# NUC123AE_v1 register map
File version: 1.0
Registers are 32-bit, read-write, reset 0x0 unless marked. A register's access mark holds for its fields unless they carry their own. Offsets are from the block's base; [hi:lo] are bit positions; {n}, {i} and the like mark numbered series; 'fields as' and 'values as' point back to an identical list.

## CLK — CLK Register Map
Base 0x50000200
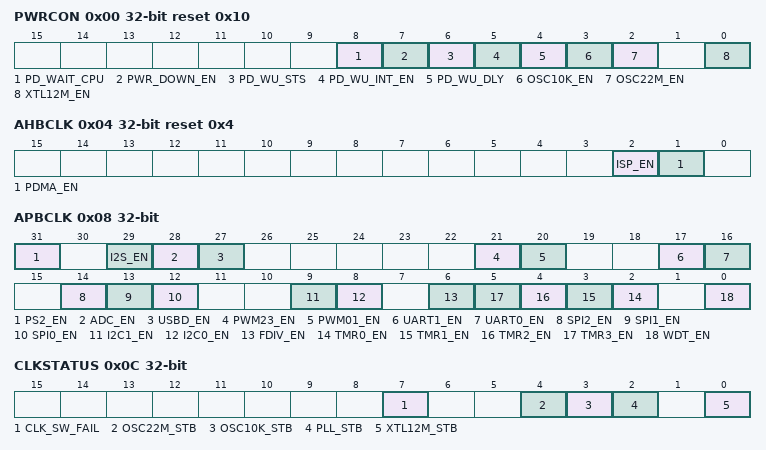
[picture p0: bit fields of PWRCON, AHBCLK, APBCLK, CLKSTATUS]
0x00 PWRCON reset 0x10 (reset mask 0xFFFFFFF0) — System Power-down Control Register
  [8] PD_WAIT_CPU — Power-down Entry Conditions Control (Write-protection Bit)
    0=Chip entering Power-down mode when the PWR_DOWN_EN bit is set to 1; 1=Chip entering Power-down mode when the both PD_WAIT_CPU and PWR_DOWN_EN bits are set to 1 and CPU run WFI instruction
  [7] PWR_DOWN_EN — System Power-down Enable Bit (Write-protection Bit). When this bit is set to 1, the chip Power-down mode is enabled and chip Power-down behavior will depend on the PD_WAIT_CPU bit. (a) If the PD_WAIT_CPU is 0, the chip enters Power-down mode immediately after the PWR_DOWN_EN bit set. (b) If the PD_WAIT_CPU is 1, the chip keeps active till the CPU sleep mode is also active and then the chip enters Power-down mode. When chip wakes up from Power-down mode, this bit is auto cleared. User needs to set this bit again for next Power-down. In Power-down mode, external 4~24 MHz high speed crystal and the internal 22.1184 MHz high speed oscillator will be disabled in this mode, but the external 32.768 kHz low speed crystal and internal 10 kHz low speed oscillator are not controlled by Power-down mode. In Power-down mode, the PLL and system clock are disabled, and ignored the clock source selection. The clocks of peripheral are not controlled by Power-down mode, if the peripheral clock source is from external 32.768 kHz low speed crystal or the internal 10 kHz low speed oscillator.
    0=Chip operating normally or chip in Idle mode because of WFI command; 1=Chip entering the Power-down mode instantly or wait CPU sleep command WFI
  [6] PD_WU_STS — Power-down Mode Wake-up Interrupt Status. Set by "Power-down wake-up event", which indicates that resume from Power-down mode" The flag is set if the GPIO, USB, UART, WDT or BOD wake-up occurred. Write 1 to clear the bit to zero. Note: This bit works only when PD_WU_INT_EN (PWRCON[5]) set to 1.
  [5] PD_WU_INT_EN — Power-down Mode Wake-up Interrupt Enable (Write-protection Bit). The interrupt will occur when both PD_WU_STS and PD_WU_INT_EN are high.
    0=Disabled; 1=Enabled
  [4] PD_WU_DLY — Enable the Wake-up Delay Counter (Write-protection Bit). When the chip wakes up from Power-down mode, the clock control will delay certain clock cycles to wait system clock stable. The delayed clock cycle is 4096 clock cycles when chip work at external 4~24 MHz high speed crystal, and 256 clock cycles when chip work at internal 22.1184 MHz high speed oscillator.
    0=Clock cycles delay Disabled; 1=Clock cycles delay Enabled
  [3] OSC10K_EN — Internal 10 kHz Low Speed Oscillator Enable (Write-protection Bit)
    0=Internal 10 kHz low speed oscillator Disabled; 1=Internal 10 kHz low speed oscillator Enabled
  [2] OSC22M_EN — Internal 22.1184 MHz High Speed Oscillator Enable (Write-protection Bit)
    0=Internal 22.1184 MHz high speed oscillator Disabled; 1=Internal 22.1184 MHz high speed oscillator Enabled
  [0] XTL12M_EN — External 4~24 MHz High Speed Crystal Enable (Write-protection Bit). The bit default value is set by flash controller user configuration register config0 [26:24]. When the default clock source is from external 4~24 MHz high speed crystal, this bit is set to 1 automatically
    0=External 4~24 MHz high speed crystal Disabled; 1=External 4~24 MHz high speed crystal Enabled
0x04 AHBCLK reset 0x4 — AHB Devices Clock Enable Control Register
  [2] ISP_EN — Flash ISP Controller Clock Enable Control
    0=Flash ISP engine clock Disabled; 1=Flash ISP engine clock Enabled
  [1] PDMA_EN — PDMA Controller Clock Enable Control
    0=PDMA engine clock Disabled; 1=PDMA engine clock Enabled
0x08 APBCLK (reset mask 0xFFFFFFF0) — APB Devices Clock Enable Control Register
  [31] PS2_EN — PS/2 Clock Enable
    0=PS/2 clock Disabled; 1=PS/2 clock Enabled
  [29] I2S_EN — I2S Clock Enable
    0=I2S Clock Disabled; 1=I2S Clock Enabled
  [28] ADC_EN — Analog-Digital-Converter (ADC) Clock Enable
    0=ADC clock Disabled; 1=ADC clock Enabled
  [27] USBD_EN — USB 2.0 FS Device Controller Clock Enable
    0=USB clock Disabled; 1=USB clock Enabled
  [21] PWM23_EN — PWM_23 Clock Enable
    0=PWM23 clock Disabled; 1=PWM23 clock Enabled
  [20] PWM01_EN — PWM_01 Clock Enable
    0=PWM01 clock Disabled; 1=PWM01 clock Enabled
  [17] UART1_EN — UART1 Clock Enable
    0=UART1 clock Disabled; 1=UART1 clock Enabled
  [16] UART0_EN — UART0 Clock Enable
    0=UART0 clock Disabled; 1=UART0 clock Enabled
  [14] SPI2_EN — SPI2 Clock Enable
    0=SPI2 clock Disabled; 1=SPI2 clock Enabled
  [13] SPI1_EN — SPI1 Clock Enable
    0=SPI1 clock Disabled; 1=SPI1 clock Enabled
  [12] SPI0_EN — SPI0 Clock Enable
    0=SPI0 clock Disabled; 1=SPI0 clock Enabled
  [9] I2C1_EN — I2C1 Clock Enable
    0=I2C1 clock Disabled; 1=I2C1 clock Enabled
  [8] I2C0_EN — I2C0 Clock Enable
    0=I2C0 clock Disabled; 1=I2C0 clock Enabled
  [6] FDIV_EN — Frequency Divider Output Clock Enable
    0=FDIV clock Disabled; 1=FDIV clock Enabled
  [n+2] TMR{n}_EN (n=0..3) — Timer{n} Clock Enable
    0=Timer{n} clock Disabled; 1=Timer{n} clock Enabled
  [0] WDT_EN — Watchdog Timer Clock Enable (Write-protection Bit). This bit is the protected bit, which means programming it needs to write "59h", "16h", "88h" to address 0x5000_0100 to disable register protection. Refer to the register REGWRPROT at address GCR_BA+0x100.
    0=Watchdog Timer Clock Disabled; 1=Watchdog Timer Clock Enabled
0x0C CLKSTATUS (reset mask 0xFFFFFF00) — Clock Status Monitor Register
  [7] CLK_SW_FAIL — Clock Switching Fail Flag. This bit is an index that if current system clock source is match as user defined at HCLK_S (CLKSEL[2:0]). When user switch system clock, the system clock source will keep old clock until the new clock is stable. During the period that waiting new clock stable, this bit will be an index shows system clock source is not match as user wanted. This bit is read only.
    0=Clock switching success; 1=Clock switching failure
  [4] OSC22M_STB — Internal 22.1184 MHz High Speed Oscillator Clock Source Stable Flag. This is read only bit
    0=Internal 22.1184 MHz high speed oscillator clock is not stable or disabled; 1=Internal 22.1184 MHz high speed oscillator clock is stable
  [3] OSC10K_STB — Internal 10 kHz Low Speed Oscillator Clock Source Stable Flag. This is read only bit.
    0=Internal 10 kHz low speed oscillator clock is not stable or disabled; 1=Internal 10 kHz low speed oscillator clock is stable
  [2] PLL_STB — Internal PLL Clock Source Stable Flag. This is read only bit.
    0=Internal PLL clock is not stable or disabled; 1=Internal PLL clock is stable
  [0] XTL12M_STB — External 4~24 MHz High Speed Crystal Clock Source Stable Flag. This is read only bit.
    0=External 4~24 MHz high speed crystal clock is not stable or disabled; 1=External 4~24 MHz high speed crystal clock is stable
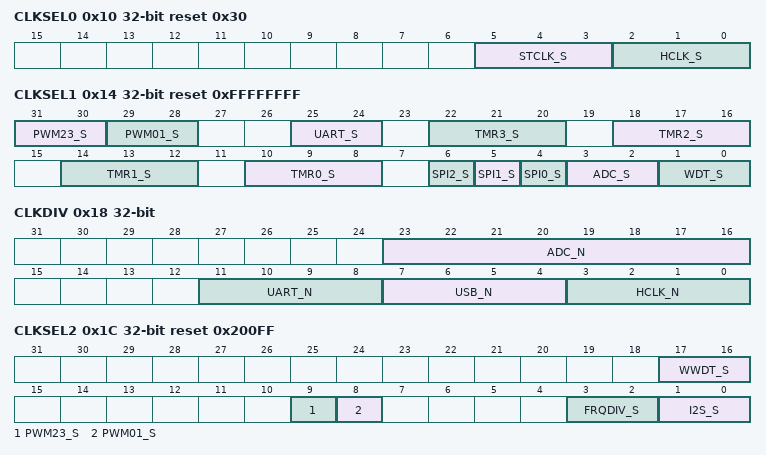
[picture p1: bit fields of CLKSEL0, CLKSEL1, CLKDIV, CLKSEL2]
0x10 CLKSEL0 reset 0x30 (reset mask 0xFFFFFFF0) — Clock Source Select Control Register 0
  [5:3] STCLK_S — Cortex_M0 SysTick Clock Source Selection (Write-protection Bits)
    0=Clock source from external 4~24 MHz high speed crystal clock; 2=Clock source from external 4~24 MHz high speed crystal clock/2; 3=Clock source from HCLK/2; 7=Clock source from internal 22.1184 MHz high speed oscillator clock/2
  [2:0] HCLK_S — HCLK Clock Source Selection (Write-protection Bits). Before clock switching, the related clock sources (both pre-select and new-select) must be turn on. The 3-bit default value is reloaded from the value of CFOSC (Config0[26:24]) in user configuration register of Flash controller by any reset. Therefore the default value is either 000b or 111b. These bits are protected bit, It means programming this bit needs to write "59h", "16h", "88h" to address 0x5000_0100 to disable register protection. Refer to the register REGWRPROT at address GCR_BA+0x100.
    0=Clock source from external 4~24 MHz high speed crystal clock; 1=Clock source from PLL clock/2; 2=Clock source from PLL clock; 3=Clock source from internal 10 kHz low speed oscillator clock; 7=Clock source from internal 22.1184 MHz high speed oscillator clock
0x14 CLKSEL1 reset 0xFFFFFFFF — Clock Source Select Control Register 1
  [31:30] PWM23_S — PWM2 and PWM3 Clock Source Select Bit [1:0]. PWM2 and PWM3 use the same Engine clock source, and both of them use the same prescaler. The Engine clock source of PWM2 and PWM3 is defined by PWM23_S[2:0] and this field is combined by CLKSEL2[9] and CLKSEL1[31:30].
  [29:28] PWM01_S — PWM0 and PWM1 Clock Source Select Bit [1:0]. PWM0 and PWM1 use the same Engine clock source, and both of them use the same prescaler. The Engine clock source of PWM0 and PWM1 is defined by PWM01_S[2:0] and this field is combined by CLKSEL2[8] and CLKSEL1[29:28].
  [25:24] UART_S — UART Clock Source Selection
    0=Clock source from external 4~24 MHz high speed crystal clock; 1=Clock source from PLL clock; 3=Clock source from internal 22.1184 MHz high speed oscillator clock
  [22:20] TMR3_S — TIMER3 Clock Source Selection
    0=Clock source from external 4~24 MHz high speed crystal clock; 2=Clock source from HCLK; 5=Clock source from internal 10 kHz low speed oscillator clock; 7=Clock source from internal 22.1184 MHz high speed oscillator clock
  [18:16] TMR2_S — TIMER2 Clock Source Selection
    0=Clock source from external 4~24 MHz high speed crystal clock; 2=Clock source from HCLK; 3=Clock source from external clock source TM2; 5=Clock source from internal 10 kHz low speed oscillator clock; 7=Clock source from internal 22.1184 MHz high speed oscillator clock
  [14:12] TMR1_S — TIMER1 Clock Source Selection
    0=Clock source from external 4~24 MHz high speed crystal clock; 2=Clock source from HCLK; 3=Clock source from external clock source TM1; 5=Clock source from internal 10 kHz low speed oscillator clock; 7=Clock source from internal 22.1184 MHz high speed oscillator clock
  [10:8] TMR0_S — TIMER0 Clock Source Selection
    0=Clock source from external 4~24 MHz high speed crystal clock; 2=Clock source from HCLK; 3=Clock source from external clock source TM0; 5=Clock source from internal 10 kHz low speed oscillator clock; 7=Clock source from internal 22.1184 MHz high speed oscillator clock
  [6] SPI2_S — SPI2 Clock Source Selection
    0=Clock source from PLL clock; 1=Clock source from HCLK
  [5] SPI1_S — SPI1 Clock Source Selection
    0=Clock source from PLL clock; 1=Clock source from HCLK
  [4] SPI0_S — SPI0 Clock Source Selection
    0=Clock source from PLL clock; 1=Clock source from HCLK
  [3:2] ADC_S — ADC Clock Source Selection
    0=Clock source from external 4~24 MHz high speed crystal clock; 1=Clock source from PLL clock; 2=Clock source from HCLK; 3=Clock source from internal 22.1184 MHz high speed oscillator clock
  [1:0] WDT_S — Watchdog Timer Clock Source Selection (Write-protection Bits). These bits are protected bits and programming this needs to write "59h", "16h", "88h" to address 0x5000_0100 to disable register protection. Refer to the register REGWRPROT at address GCR_BA+0x100.
    2=Clock source from HCLK/2048 clock; 3=Clock source from internal 10 kHz low speed oscillator clock
0x18 CLKDIV — Clock Divider Number Register
  [23:16] ADC_N — ADC Clock Divide Number from ADC Clock Source
  [11:8] UART_N — UART Clock Divide Number from UART Clock Source
  [7:4] USB_N — USB Clock Divide Number from PLL Clock
  [3:0] HCLK_N — HCLK Clock Divide Number from HCLK Clock Source
0x1C CLKSEL2 reset 0x200FF — Clock Source Select Control Register 2
  [17:16] WWDT_S — Windowed-Watchdog Timer Clock Source Selection (Write-protection Bits)
    values as CLKSEL1.WDT_S
  [9] PWM23_S — PWM2 and PWM3 Clock Source Select Bit [2]. PWM2 and PWM3 use the same Engine clock source, and both of them use the same prescaler. The Engine clock source of PWM2 and PWM3 is defined by PWM23_S[2:0] and this field is combined by CLKSEL2[9] and CLKSEL1[31:30].
  [8] PWM01_S — PWM0 and PWM1 Clock Source Select Bit [2]. PWM0 and PWM1 use the same Engine clock source, and both of them use the same prescaler. The Engine clock source of PWM0 and PWM1 is defined by PWM01_S[2:0] and this field is combined by CLKSEL2[8] and CLKSEL1[29:28].
  [3:2] FRQDIV_S — Clock Divider Clock Source Selection
    0=Clock source from external 4~24 MHz high speed crystal clock; 2=Clock source from HCLK; 3=Clock source from internal 22.1184 MHz high speed oscillator clock
  [1:0] I2S_S — I2S Clock Source Selection
    values as CLKSEL1.ADC_S
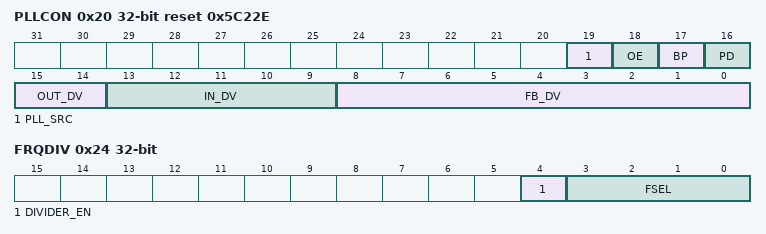
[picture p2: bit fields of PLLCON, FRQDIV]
0x20 PLLCON reset 0x5C22E — PLL Control Register
  [19] PLL_SRC — PLL Source Clock Selection
    0=PLL source clock from external 4~24 MHz high speed crystal; 1=PLL source clock from internal 22.1184 MHz high speed oscillator
  [18] OE — PLL OE (FOUT Enable) Pin Control
    0=PLL FOUT Enabled; 1=PLL FOUT is fixed low
  [17] BP — PLL Bypass Control
    0=PLL is in Normal mode (default); 1=PLL clock output is the same as clock input (XTALin)
  [16] PD — Power-down Mode. If the PWR_DOWN_EN bit set to 1 in PWRCON register, the PLL will also enter Power-down mode.
    0=PLL is in Normal mode; 1=PLL is in Power-down mode (default)
  [15:14] OUT_DV — PLL Output Divider Control Pins. Refer to the formulas below the table.
  [13:9] IN_DV — PLL Input Divider Control Pins. Refer to the formulas below the table.
  [8:0] FB_DV — PLL Feedback Divider Control Pins. Refer to the formulas below the table.
0x24 FRQDIV — Frequency Divider Control Register
  [4] DIVIDER_EN — Frequency Divider Enable Bit
    0=Frequency Divider Disabled; 1=Frequency Divider Enabled
  [3:0] FSEL — Divider Output Frequency Select Bits. The formula of output frequency is: Fin is the input clock frequency. Fout is the frequency of divider output clock. N is the 4-bit value of FSEL[3:0].
0x2C APBDIV — APB Divider Control Register
  [0] APBDIV — APB Divider Enable Bit
